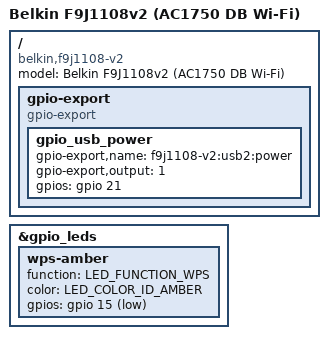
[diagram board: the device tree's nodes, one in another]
// SPDX-License-Identifier: GPL-2.0-or-later OR MIT
/dts-v1/;

#include "qca9558_belkin_f9xyyy-v2.dtsi"

/ {
	model = "Belkin F9J1108v2 (AC1750 DB Wi-Fi)";
	compatible = "belkin,f9j1108-v2", "qca,qca9558";

	gpio-export {
		compatible = "gpio-export";
		#size-cells = <0>;

		gpio_usb_power {
			gpio-export,name = "f9j1108-v2:usb2:power";
			gpio-export,output = <1>;
			gpios = <&gpio 21 GPIO_ACTIVE_HIGH>;
		};
	};
};

&gpio_leds {
	wps-amber {
		function = LED_FUNCTION_WPS;
		color = <LED_COLOR_ID_AMBER>;
		gpios = <&gpio 15 GPIO_ACTIVE_LOW>;
	};
};
